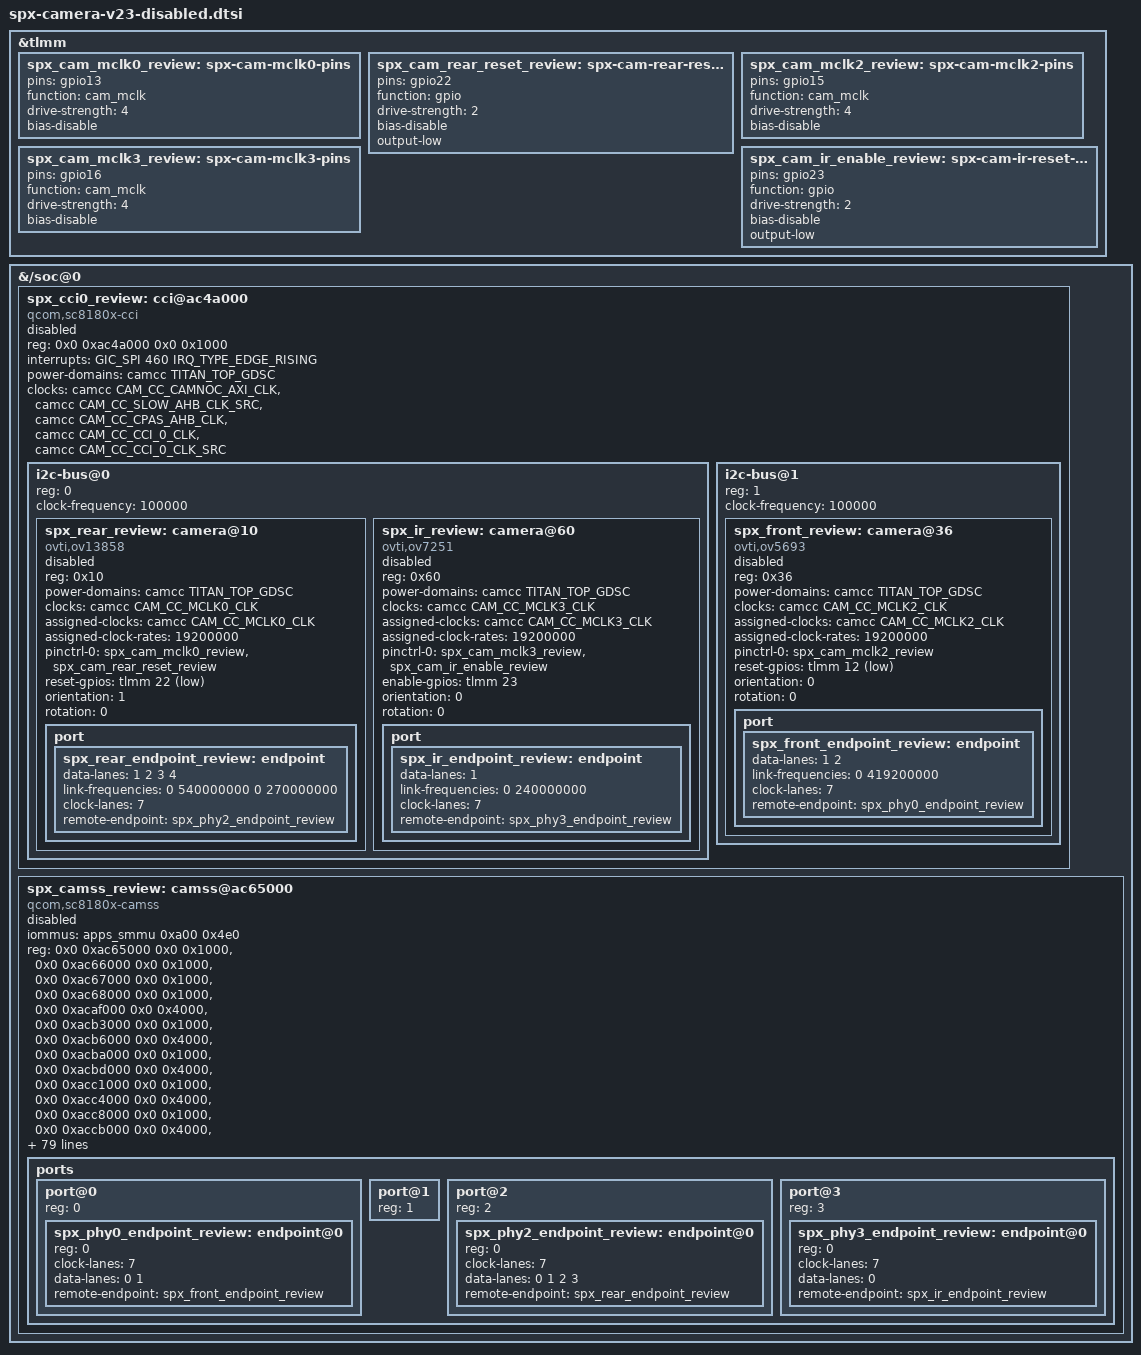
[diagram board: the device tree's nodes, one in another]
// SPDX-License-Identifier: GPL-2.0-only
/*
 * OFFLINE REVIEW ONLY: generated from the hash-pinned v23 artifact.
 * All camera/controller nodes are disabled; do not deploy or enable.
 * Supply properties and fake fixed regulators are intentionally absent.
 * The tested capture depended on separate direct SPMI rail setup.
 */

#include <dt-bindings/clock/qcom,sc8180x-camcc.h>
#include <dt-bindings/clock/qcom,gcc-sc8180x.h>
#include <dt-bindings/gpio/gpio.h>
#include <dt-bindings/interrupt-controller/arm-gic.h>
#include <dt-bindings/interconnect/qcom,sc8180x.h>
#include <dt-bindings/interconnect/qcom,icc.h>

&tlmm {
	spx_cam_mclk0_review: spx-cam-mclk0-pins {
		pins = "gpio13";
		function = "cam_mclk";
		drive-strength = <4>;
		bias-disable;
	};

	spx_cam_rear_reset_review: spx-cam-rear-reset-pins {
		pins = "gpio22";
		function = "gpio";
		drive-strength = <2>;
		bias-disable;
		output-low;
	};

	spx_cam_mclk2_review: spx-cam-mclk2-pins {
		pins = "gpio15";
		function = "cam_mclk";
		drive-strength = <4>;
		bias-disable;
	};

	spx_cam_mclk3_review: spx-cam-mclk3-pins {
		pins = "gpio16";
		function = "cam_mclk";
		drive-strength = <4>;
		bias-disable;
	};

	spx_cam_ir_enable_review: spx-cam-ir-reset-pins {
		pins = "gpio23";
		function = "gpio";
		drive-strength = <2>;
		bias-disable;
		output-low;
	};

};

&{/soc@0} {
	spx_cci0_review: cci@ac4a000 {
		compatible = "qcom,sc8180x-cci", "qcom,msm8996-cci";
		#address-cells = <1>;
		#size-cells = <0>;
		reg = <0x0 0xac4a000 0x0 0x1000>;
		interrupts = <GIC_SPI 460 IRQ_TYPE_EDGE_RISING>;
		power-domains = <&camcc TITAN_TOP_GDSC>;
		clocks = <&camcc CAM_CC_CAMNOC_AXI_CLK>, <&camcc CAM_CC_SLOW_AHB_CLK_SRC>, <&camcc CAM_CC_CPAS_AHB_CLK>, <&camcc CAM_CC_CCI_0_CLK>, <&camcc CAM_CC_CCI_0_CLK_SRC>;
		clock-names = "camnoc_axi", "slow_ahb_src", "cpas_ahb", "cci", "cci_src";
		status = "disabled";

		i2c-bus@0 {
			reg = <0>;
			clock-frequency = <100000>;
			#address-cells = <1>;
			#size-cells = <0>;

			spx_rear_review: camera@10 {
				compatible = "ovti,ov13858";
				reg = <0x10>;
				power-domains = <&camcc TITAN_TOP_GDSC>;
				clocks = <&camcc CAM_CC_MCLK0_CLK>;
				clock-names = "xvclk";
				assigned-clocks = <&camcc CAM_CC_MCLK0_CLK>;
				assigned-clock-rates = <19200000>;
				pinctrl-names = "default";
				pinctrl-0 = <&spx_cam_mclk0_review &spx_cam_rear_reset_review>;
				reset-gpios = <&tlmm 22 GPIO_ACTIVE_LOW>;
				/* Unresolved real rail provider: no placeholder supplies. */
				orientation = <1>;
				rotation = <0>;
				status = "disabled";

				port {
					spx_rear_endpoint_review: endpoint {
						data-lanes = <1 2 3 4>;
						link-frequencies = <0 540000000 0 270000000>;
						clock-lanes = <7>;
						remote-endpoint = <&spx_phy2_endpoint_review>;
					};
				};
			};

			spx_ir_review: camera@60 {
				compatible = "ovti,ov7251";
				reg = <0x60>;
				power-domains = <&camcc TITAN_TOP_GDSC>;
				clocks = <&camcc CAM_CC_MCLK3_CLK>;
				clock-names = "xclk";
				assigned-clocks = <&camcc CAM_CC_MCLK3_CLK>;
				assigned-clock-rates = <19200000>;
				pinctrl-names = "default";
				pinctrl-0 = <&spx_cam_mclk3_review &spx_cam_ir_enable_review>;
				enable-gpios = <&tlmm 23 GPIO_ACTIVE_HIGH>;
				/* Unresolved real rail provider: no placeholder supplies. */
				orientation = <0>;
				rotation = <0>;
				status = "disabled";

				port {
					spx_ir_endpoint_review: endpoint {
						data-lanes = <1>;
						link-frequencies = <0 240000000>;
						clock-lanes = <7>;
						remote-endpoint = <&spx_phy3_endpoint_review>;
					};
				};
			};

		};

		i2c-bus@1 {
			reg = <1>;
			clock-frequency = <100000>;
			#address-cells = <1>;
			#size-cells = <0>;

			spx_front_review: camera@36 {
				compatible = "ovti,ov5693";
				reg = <0x36>;
				power-domains = <&camcc TITAN_TOP_GDSC>;
				clocks = <&camcc CAM_CC_MCLK2_CLK>;
				clock-names = "xvclk";
				assigned-clocks = <&camcc CAM_CC_MCLK2_CLK>;
				assigned-clock-rates = <19200000>;
				pinctrl-names = "default";
				pinctrl-0 = <&spx_cam_mclk2_review>;
				reset-gpios = <&tlmm 12 GPIO_ACTIVE_LOW>;
				/* Unresolved real rail provider: no placeholder supplies. */
				orientation = <0>;
				rotation = <0>;
				status = "disabled";

				port {
					spx_front_endpoint_review: endpoint {
						data-lanes = <1 2>;
						link-frequencies = <0 419200000>;
						clock-lanes = <7>;
						remote-endpoint = <&spx_phy0_endpoint_review>;
					};
				};
			};

		};

	};

	spx_camss_review: camss@ac65000 {
		compatible = "qcom,sc8180x-camss";
		iommus = <&apps_smmu 0xa00 0x4e0>;
		reg = <0x0 0xac65000 0x0 0x1000>,
		      <0x0 0xac66000 0x0 0x1000>,
		      <0x0 0xac67000 0x0 0x1000>,
		      <0x0 0xac68000 0x0 0x1000>,
		      <0x0 0xacaf000 0x0 0x4000>,
		      <0x0 0xacb3000 0x0 0x1000>,
		      <0x0 0xacb6000 0x0 0x4000>,
		      <0x0 0xacba000 0x0 0x1000>,
		      <0x0 0xacbd000 0x0 0x4000>,
		      <0x0 0xacc1000 0x0 0x1000>,
		      <0x0 0xacc4000 0x0 0x4000>,
		      <0x0 0xacc8000 0x0 0x1000>,
		      <0x0 0xaccb000 0x0 0x4000>,
		      <0x0 0xaccf000 0x0 0x1000>,
		      <0x0 0xacd2000 0x0 0x4000>,
		      <0x0 0xacd6000 0x0 0x1000>,
		      <0x0 0xacd9000 0x0 0x4000>,
		      <0x0 0xacdd000 0x0 0x1000>,
		      <0x0 0xace0000 0x0 0x4000>,
		      <0x0 0xace4000 0x0 0x1000>;
		reg-names = "csiphy0", "csiphy1", "csiphy2", "csiphy3", "vfe0", "csid0", "vfe1", "csid1", "vfe2", "csid2", "vfe_lite0", "csid0_lite", "vfe_lite1", "csid1_lite", "vfe_lite2", "csid2_lite", "vfe_lite3", "csid3_lite", "vfe3", "csid3";
		interrupts = <GIC_SPI 359 IRQ_TYPE_EDGE_RISING>,
			     <GIC_SPI 360 IRQ_TYPE_EDGE_RISING>,
			     <GIC_SPI 448 IRQ_TYPE_EDGE_RISING>,
			     <GIC_SPI 464 IRQ_TYPE_EDGE_RISING>,
			     <GIC_SPI 465 IRQ_TYPE_EDGE_RISING>,
			     <GIC_SPI 466 IRQ_TYPE_EDGE_RISING>,
			     <GIC_SPI 467 IRQ_TYPE_EDGE_RISING>,
			     <GIC_SPI 468 IRQ_TYPE_EDGE_RISING>,
			     <GIC_SPI 469 IRQ_TYPE_EDGE_RISING>,
			     <GIC_SPI 477 IRQ_TYPE_EDGE_RISING>,
			     <GIC_SPI 478 IRQ_TYPE_EDGE_RISING>,
			     <GIC_SPI 479 IRQ_TYPE_EDGE_RISING>,
			     <GIC_SPI 462 IRQ_TYPE_EDGE_RISING>,
			     <GIC_SPI 463 IRQ_TYPE_EDGE_RISING>,
			     <GIC_SPI 476 IRQ_TYPE_EDGE_RISING>,
			     <GIC_SPI 759 IRQ_TYPE_EDGE_RISING>,
			     <GIC_SPI 760 IRQ_TYPE_EDGE_RISING>,
			     <GIC_SPI 761 IRQ_TYPE_EDGE_RISING>,
			     <GIC_SPI 762 IRQ_TYPE_EDGE_RISING>,
			     <GIC_SPI 764 IRQ_TYPE_EDGE_RISING>;
		interrupt-names = "csid1_lite", "vfe_lite1", "csiphy3", "csid0", "vfe0", "csid1", "vfe1", "csid0_lite", "vfe_lite0", "csiphy0", "csiphy1", "csiphy2", "csid2", "vfe2", "csid3_lite", "csid2_lite", "vfe_lite3", "vfe_lite2", "csid3", "vfe3";
		power-domains = <&camcc IFE_0_GDSC>, <&camcc IFE_1_GDSC>, <&camcc IFE_2_GDSC>, <&camcc IFE_3_GDSC>, <&camcc TITAN_TOP_GDSC>;
		power-domain-names = "ife0", "ife1", "ife2", "ife3", "top";
		clocks = <&camcc CAM_CC_CAMNOC_AXI_CLK>, <&camcc CAM_CC_CPAS_AHB_CLK>, <&camcc CAM_CC_CSIPHY0_CLK>, <&camcc CAM_CC_CSI0PHYTIMER_CLK>, <&camcc CAM_CC_CSIPHY1_CLK>, <&camcc CAM_CC_CSI1PHYTIMER_CLK>, <&camcc CAM_CC_CSIPHY2_CLK>, <&camcc CAM_CC_CSI2PHYTIMER_CLK>, <&camcc CAM_CC_CSIPHY3_CLK>, <&camcc CAM_CC_CSI3PHYTIMER_CLK>, <&camcc CAM_CC_IFE_0_AXI_CLK>, <&camcc CAM_CC_IFE_0_CLK>, <&camcc CAM_CC_IFE_0_CPHY_RX_CLK>, <&camcc CAM_CC_IFE_0_CSID_CLK>, <&camcc CAM_CC_IFE_1_AXI_CLK>, <&camcc CAM_CC_IFE_1_CLK>, <&camcc CAM_CC_IFE_1_CPHY_RX_CLK>, <&camcc CAM_CC_IFE_1_CSID_CLK>, <&camcc CAM_CC_IFE_2_AXI_CLK>, <&camcc CAM_CC_IFE_2_CLK>, <&camcc CAM_CC_IFE_2_CPHY_RX_CLK>, <&camcc CAM_CC_IFE_2_CSID_CLK>, <&camcc CAM_CC_IFE_3_AXI_CLK>, <&camcc CAM_CC_IFE_3_CLK>, <&camcc CAM_CC_IFE_3_CPHY_RX_CLK>, <&camcc CAM_CC_IFE_3_CSID_CLK>, <&camcc CAM_CC_IFE_LITE_0_CLK>, <&camcc CAM_CC_IFE_LITE_0_CPHY_RX_CLK>, <&camcc CAM_CC_IFE_LITE_0_CSID_CLK>, <&camcc CAM_CC_IFE_LITE_1_CLK>, <&camcc CAM_CC_IFE_LITE_1_CPHY_RX_CLK>, <&camcc CAM_CC_IFE_LITE_1_CSID_CLK>, <&camcc CAM_CC_IFE_LITE_2_CLK>, <&camcc CAM_CC_IFE_LITE_2_CPHY_RX_CLK>, <&camcc CAM_CC_IFE_LITE_2_CSID_CLK>, <&camcc CAM_CC_IFE_LITE_3_CLK>, <&camcc CAM_CC_IFE_LITE_3_CPHY_RX_CLK>, <&camcc CAM_CC_IFE_LITE_3_CSID_CLK>, <&gcc GCC_CAMERA_HF_AXI_CLK>, <&gcc GCC_CAMERA_SF_AXI_CLK>;
		clock-names = "camnoc_axi", "cpas_ahb", "csiphy0", "csiphy0_timer", "csiphy1", "csiphy1_timer", "csiphy2", "csiphy2_timer", "csiphy3", "csiphy3_timer", "vfe0_axi", "vfe0", "vfe0_cphy_rx", "vfe0_csid", "vfe1_axi", "vfe1", "vfe1_cphy_rx", "vfe1_csid", "vfe2_axi", "vfe2", "vfe2_cphy_rx", "vfe2_csid", "vfe3_axi", "vfe3", "vfe3_cphy_rx", "vfe3_csid", "vfe_lite0", "vfe_lite0_cphy_rx", "vfe_lite0_csid", "vfe_lite1", "vfe_lite1_cphy_rx", "vfe_lite1_csid", "vfe_lite2", "vfe_lite2_cphy_rx", "vfe_lite2_csid", "vfe_lite3", "vfe_lite3_cphy_rx", "vfe_lite3_csid", "gcc_axi_hf", "gcc_axi_sf";
		interconnects = <&gem_noc MASTER_AMPSS_M0 QCOM_ICC_TAG_ACTIVE_ONLY &config_noc SLAVE_CAMERA_CFG QCOM_ICC_TAG_ACTIVE_ONLY>,
				<&mmss_noc MASTER_CAMNOC_HF0 QCOM_ICC_TAG_ACTIVE_ONLY &mc_virt SLAVE_EBI_CH0 QCOM_ICC_TAG_ACTIVE_ONLY>,
				<&mmss_noc MASTER_CAMNOC_SF QCOM_ICC_TAG_ACTIVE_ONLY &mc_virt SLAVE_EBI_CH0 QCOM_ICC_TAG_ACTIVE_ONLY>,
				<&mmss_noc MASTER_CAMNOC_HF1 QCOM_ICC_TAG_ACTIVE_ONLY &mc_virt SLAVE_EBI_CH0 QCOM_ICC_TAG_ACTIVE_ONLY>;
		interconnect-names = "cam_ahb", "cam_hf_mnoc", "cam_sf_mnoc", "cam_sf_icp_mnoc";
		status = "disabled";

		ports {
			#address-cells = <1>;
			#size-cells = <0>;

			port@0 {
				reg = <0>;
				#address-cells = <1>;
				#size-cells = <0>;

				spx_phy0_endpoint_review: endpoint@0 {
					reg = <0>;
					clock-lanes = <7>;
					data-lanes = <0 1>;
					remote-endpoint = <&spx_front_endpoint_review>;
				};
			};

			port@1 {
				reg = <1>;
				#address-cells = <1>;
				#size-cells = <0>;
			};

			port@2 {
				reg = <2>;
				#address-cells = <1>;
				#size-cells = <0>;

				spx_phy2_endpoint_review: endpoint@0 {
					reg = <0>;
					clock-lanes = <7>;
					data-lanes = <0 1 2 3>;
					remote-endpoint = <&spx_rear_endpoint_review>;
				};
			};

			port@3 {
				reg = <3>;
				#address-cells = <1>;
				#size-cells = <0>;

				spx_phy3_endpoint_review: endpoint@0 {
					reg = <0>;
					clock-lanes = <7>;
					data-lanes = <0>;
					remote-endpoint = <&spx_ir_endpoint_review>;
				};
			};

		};
	};
};
